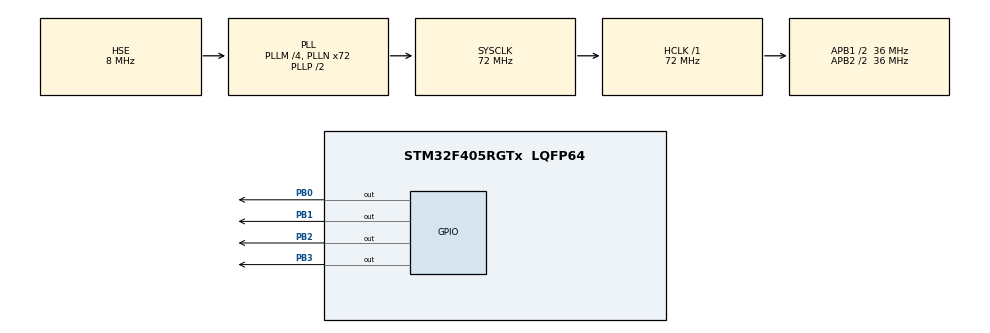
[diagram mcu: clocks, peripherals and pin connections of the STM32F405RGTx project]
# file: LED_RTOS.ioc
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FREERTOS.Tasks01=LED_Task,0,128,LED_Thread,Default,NULL,Dynamic,NULL,NULL;LED_Task1,-3,128,LED_Thread1,Default,NULL,Dynamic,NULL,NULL;LED_Task2,-3,128,LED_Thread2,Default,NULL,Dynamic,NULL,NULL;LED_Task3,-3,128,LED_Thread3,Default,NULL,Dynamic,NULL,NULL
FREERTOS.configUSE_NEWLIB_REENTRANT=1
Mcu.Family=STM32F4
Mcu.Name=STM32F405RGTx
Mcu.Package=LQFP64
NVIC.PriorityGroup=NVIC_PRIORITYGROUP_4
NVIC.TIM1_UP_TIM10_IRQn=true\:15\:0\:false\:false\:true\:false\:false\:true\:true
NVIC.TimeBase=TIM1_UP_TIM10_IRQn
NVIC.TimeBaseIP=TIM1
PA13.Mode=Serial_Wire
PA13.Signal=SYS_JTMS-SWDIO
PA14.Mode=Serial_Wire
PA14.Signal=SYS_JTCK-SWCLK
PB0.PinState=GPIO_PIN_SET
PB0.Signal=GPIO_Output
PB1.PinState=GPIO_PIN_SET
PB1.Signal=GPIO_Output
PB2.PinState=GPIO_PIN_SET
PB2.Signal=GPIO_Output
PB3.PinState=GPIO_PIN_SET
PB3.Signal=GPIO_Output
PH0-OSC_IN.Mode=HSE-External-Oscillator
PH0-OSC_IN.Signal=RCC_OSC_IN
PH1-OSC_OUT.Mode=HSE-External-Oscillator
PH1-OSC_OUT.Signal=RCC_OSC_OUT
ProjectManager.HeapSize=0x200
ProjectManager.StackSize=0x400
ProjectManager.TargetToolchain=STM32CubeIDE
RCC.48MHZClocksFreq_Value=36000000
RCC.AHBFreq_Value=72000000
RCC.APB1CLKDivider=RCC_HCLK_DIV2
RCC.APB1Freq_Value=36000000
RCC.APB1TimFreq_Value=72000000
RCC.APB2CLKDivider=RCC_HCLK_DIV2
RCC.APB2Freq_Value=36000000
RCC.APB2TimFreq_Value=72000000
RCC.CortexFreq_Value=72000000
RCC.HCLKFreq_Value=72000000
RCC.HSE_VALUE=8000000
RCC.HSI_VALUE=16000000
RCC.LSE_VALUE=32768
RCC.PLLM=4
RCC.PLLN=72
RCC.PLLSourceVirtual=RCC_PLLSOURCE_HSE
RCC.SYSCLKFreq_VALUE=72000000
RCC.SYSCLKSource=RCC_SYSCLKSOURCE_PLLCLK
RCC.VCOOutputFreq_Value=144000000
VP_FREERTOS_VS_CMSIS_V1.Mode=CMSIS_V1
VP_SYS_VS_tim1.Mode=TIM1
board=custom

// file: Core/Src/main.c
/* USER CODE BEGIN Header */
/**
  ******************************************************************************
  * @file           : main.c
  * @brief          : Main program body
  ******************************************************************************
  * @attention
  *
  * Copyright (c) 2023 STMicroelectronics.
  * All rights reserved.
  *
  * This software is licensed under terms that can be found in the LICENSE file
  * in the root directory of this software component.
  * If no LICENSE file comes with this software, it is provided AS-IS.
  *
  ******************************************************************************
  */
/* USER CODE END Header */
#include "main.h"
#include "cmsis_os.h"

osThreadId LED_TaskHandle;
osThreadId LED_Task1Handle;
osThreadId LED_Task2Handle;
osThreadId LED_Task3Handle;
/* USER CODE BEGIN PV */

#define delay_500 500
#define delay_1000 1000
#define delay_2000 2000
#define delay_3000 3000
/* USER CODE END PV */

void SystemClock_Config(void);
static void MX_GPIO_Init(void);
void LED_Thread(void const * argument);
void LED_Thread1(void const * argument);
void LED_Thread2(void const * argument);
void LED_Thread3(void const * argument);

int main(void)
{

  /* MCU Configuration--------------------------------------------------------*/

  /* Reset of all peripherals, Initializes the Flash interface and the Systick. */
  HAL_Init();

  /* Configure the system clock */
  SystemClock_Config();

  /* Initialize all configured peripherals */
  MX_GPIO_Init();

  /* Create the thread(s) */
  /* definition and creation of LED_Task */
  osThreadDef(LED_Task, LED_Thread, osPriorityNormal, 0, 128);
  LED_TaskHandle = osThreadCreate(osThread(LED_Task), NULL);

  /* definition and creation of LED_Task1 */
  osThreadDef(LED_Task1, LED_Thread1, osPriorityIdle, 0, 128);
  LED_Task1Handle = osThreadCreate(osThread(LED_Task1), NULL);

  /* definition and creation of LED_Task2 */
  osThreadDef(LED_Task2, LED_Thread2, osPriorityIdle, 0, 128);
  LED_Task2Handle = osThreadCreate(osThread(LED_Task2), NULL);

  /* definition and creation of LED_Task3 */
  osThreadDef(LED_Task3, LED_Thread3, osPriorityIdle, 0, 128);
  LED_Task3Handle = osThreadCreate(osThread(LED_Task3), NULL);

  /* Start scheduler */
  osKernelStart();

  /* We should never get here as control is now taken by the scheduler */
  /* Infinite loop */
  while (1)
  {

  }
}

void SystemClock_Config(void)
{
  RCC_OscInitTypeDef RCC_OscInitStruct = {0};
  RCC_ClkInitTypeDef RCC_ClkInitStruct = {0};

  /** Configure the main internal regulator output voltage
  */
  __HAL_RCC_PWR_CLK_ENABLE();
  __HAL_PWR_VOLTAGESCALING_CONFIG(PWR_REGULATOR_VOLTAGE_SCALE1);

  /** Initializes the RCC Oscillators according to the specified parameters
  * in the RCC_OscInitTypeDef structure.
  */
  RCC_OscInitStruct.OscillatorType = RCC_OSCILLATORTYPE_HSE;
  RCC_OscInitStruct.HSEState = RCC_HSE_ON;
  RCC_OscInitStruct.PLL.PLLState = RCC_PLL_ON;
  RCC_OscInitStruct.PLL.PLLSource = RCC_PLLSOURCE_HSE;
  RCC_OscInitStruct.PLL.PLLM = 4;
  RCC_OscInitStruct.PLL.PLLN = 72;
  RCC_OscInitStruct.PLL.PLLP = RCC_PLLP_DIV2;
  RCC_OscInitStruct.PLL.PLLQ = 4;
  if (HAL_RCC_OscConfig(&RCC_OscInitStruct) != HAL_OK)
  {
    Error_Handler();
  }

  /** Initializes the CPU, AHB and APB buses clocks
  */
  RCC_ClkInitStruct.ClockType = RCC_CLOCKTYPE_HCLK|RCC_CLOCKTYPE_SYSCLK
                              |RCC_CLOCKTYPE_PCLK1|RCC_CLOCKTYPE_PCLK2;
  RCC_ClkInitStruct.SYSCLKSource = RCC_SYSCLKSOURCE_PLLCLK;
  RCC_ClkInitStruct.AHBCLKDivider = RCC_SYSCLK_DIV1;
  RCC_ClkInitStruct.APB1CLKDivider = RCC_HCLK_DIV2;
  RCC_ClkInitStruct.APB2CLKDivider = RCC_HCLK_DIV2;

  if (HAL_RCC_ClockConfig(&RCC_ClkInitStruct, FLASH_LATENCY_2) != HAL_OK)
  {
    Error_Handler();
  }
}

static void MX_GPIO_Init(void)
{
  GPIO_InitTypeDef GPIO_InitStruct = {0};

  /* GPIO Ports Clock Enable */
  __HAL_RCC_GPIOH_CLK_ENABLE();
  __HAL_RCC_GPIOB_CLK_ENABLE();
  __HAL_RCC_GPIOA_CLK_ENABLE();

  /*Configure GPIO pin Output Level */
  HAL_GPIO_WritePin(GPIOB, GPIO_PIN_0|GPIO_PIN_1|GPIO_PIN_2|GPIO_PIN_3, GPIO_PIN_SET);

  /*Configure GPIO pins : PB0 PB1 PB2 PB3 */
  GPIO_InitStruct.Pin = GPIO_PIN_0|GPIO_PIN_1|GPIO_PIN_2|GPIO_PIN_3;
  GPIO_InitStruct.Mode = GPIO_MODE_OUTPUT_PP;
  GPIO_InitStruct.Pull = GPIO_NOPULL;
  GPIO_InitStruct.Speed = GPIO_SPEED_FREQ_LOW;
  HAL_GPIO_Init(GPIOB, &GPIO_InitStruct);

}

void LED_Thread(void const * argument)
{
  /* USER CODE BEGIN 5 */
						//	uint32_t led_delay = (uint32_t)argument;
  /* Infinite loop */

	    while (1) {
//	        HAL_GPIO_WritePin(GPIOB, GPIO_PIN_0, GPIO_PIN_SET);
//	        osDelay(delay_500);
//
//	        HAL_GPIO_WritePin(GPIOB, GPIO_PIN_0, GPIO_PIN_RESET);
//	        osDelay(delay_500);

			HAL_GPIO_TogglePin(GPIOB, GPIO_PIN_0);
			osDelay(500);
	    }
  /* USER CODE END 5 */
}

void LED_Thread1(void const * argument)
{
  /* USER CODE BEGIN LED_Thread1 */
							//uint32_t led_delay = (uint32_t)argument;
  /* Infinite loop */
    while (1) {
//        HAL_GPIO_WritePin(GPIOB, GPIO_PIN_1, GPIO_PIN_SET);
//        osDelay(delay_1000);
//
//        HAL_GPIO_WritePin(GPIOB, GPIO_PIN_1, GPIO_PIN_RESET);
//        osDelay(delay_1000);
        HAL_GPIO_TogglePin(GPIOB, GPIO_PIN_1);
        osDelay(1000);
    }
  /* USER CODE END LED_Thread1 */
}

void LED_Thread2(void const * argument)
{
  /* USER CODE BEGIN LED_Thread2 */
						//uint32_t led_delay = (uint32_t)argument;
  /* Infinite loop */
    while (1) {
//        HAL_GPIO_WritePin(GPIOB, GPIO_PIN_2, GPIO_PIN_SET);
//        osDelay(delay_2000);
//
//        HAL_GPIO_WritePin(GPIOB, GPIO_PIN_2, GPIO_PIN_RESET);
//        osDelay(delay_2000);
    	HAL_GPIO_TogglePin(GPIOB, GPIO_PIN_2);
    	osDelay(2000);
    }
  /* USER CODE END LED_Thread2 */
}

void LED_Thread3(void const * argument)
{
  /* USER CODE BEGIN LED_Thread3 */
					//uint32_t led_delay = (uint32_t)argument;
  /* Infinite loop */
    while (1) {
//        HAL_GPIO_WritePin(GPIOB, GPIO_PIN_3, GPIO_PIN_SET);
//        osDelay(delay_3000);
//
//        HAL_GPIO_WritePin(GPIOB, GPIO_PIN_, GPIO_PIN_RESET);
//        osDelay(delay_3000);

    	HAL_GPIO_TogglePin(GPIOB, GPIO_PIN_3);
    	osDelay(3000);
    }
  /* USER CODE END LED_Thread3 */
}

void HAL_TIM_PeriodElapsedCallback(TIM_HandleTypeDef *htim)
{
  if (htim->Instance == TIM1) {
    HAL_IncTick();
  }
}

void Error_Handler(void)
{
  __disable_irq();
  while (1)
  {
  }
}
